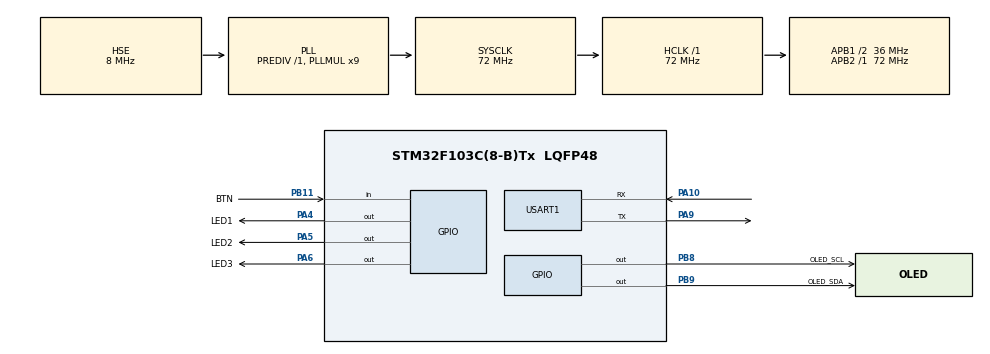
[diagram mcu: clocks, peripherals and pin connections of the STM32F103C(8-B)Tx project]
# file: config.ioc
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FREERTOS.Queues01=LEDCmdQueue,10,LEDCmdType,0,Dynamic,NULL,NULL;UARTStrQueue,5,16,1,Dynamic,NULL,NULL
FREERTOS.Tasks01=LEDTask,24,128,StartLEDTask,As weak,NULL,Dynamic,NULL,NULL;BtnTask,40,128,StartBtnTask,As weak,NULL,Dynamic,NULL,NULL;CommandTask,41,128,StartCommandTask,As weak,NULL,Dynamic,NULL,NULL
FREERTOS.configGENERATE_RUN_TIME_STATS=1
FREERTOS.configRECORD_STACK_HIGH_ADDRESS=1
FREERTOS.configUSE_STATS_FORMATTING_FUNCTIONS=0
Mcu.Family=STM32F1
Mcu.Name=STM32F103C(8-B)Tx
Mcu.Package=LQFP48
NVIC.PriorityGroup=NVIC_PRIORITYGROUP_4
NVIC.TIM4_IRQn=true\:15\:0\:false\:false\:true\:false\:false\:true\:true
NVIC.TimeBase=TIM4_IRQn
NVIC.TimeBaseIP=TIM4
NVIC.USART1_IRQn=true\:5\:0\:false\:false\:true\:true\:true\:true\:true
PA10.Mode=Asynchronous
PA10.Signal=USART1_RX
PA13.Mode=Serial_Wire
PA13.Signal=SYS_JTMS-SWDIO
PA14.Mode=Serial_Wire
PA14.Signal=SYS_JTCK-SWCLK
PA4.GPIO_Label=LED1
PA4.GPIO_Speed=GPIO_SPEED_FREQ_HIGH
PA4.Signal=GPIO_Output
PA5.GPIO_Label=LED2
PA5.GPIO_Speed=GPIO_SPEED_FREQ_HIGH
PA5.Signal=GPIO_Output
PA6.GPIO_Label=LED3
PA6.GPIO_Speed=GPIO_SPEED_FREQ_HIGH
PA6.Signal=GPIO_Output
PA9.Mode=Asynchronous
PA9.Signal=USART1_TX
PB11.GPIO_Label=BTN
PB11.GPIO_PuPd=GPIO_PULLUP
PB11.Signal=GPIO_Input
PB8.GPIO_Label=OLED_SCL
PB8.GPIO_ModeDefaultOutputPP=GPIO_MODE_OUTPUT_OD
PB8.GPIO_PuPd=GPIO_NOPULL
PB8.GPIO_Speed=GPIO_SPEED_FREQ_HIGH
PB8.PinState=GPIO_PIN_SET
PB8.Signal=GPIO_Output
PB9.GPIO_Label=OLED_SDA
PB9.GPIO_ModeDefaultOutputPP=GPIO_MODE_OUTPUT_OD
PB9.GPIO_PuPd=GPIO_NOPULL
PB9.GPIO_Speed=GPIO_SPEED_FREQ_HIGH
PB9.PinState=GPIO_PIN_SET
PB9.Signal=GPIO_Output
PD0-OSC_IN.Mode=HSE-External-Oscillator
PD0-OSC_IN.Signal=RCC_OSC_IN
PD1-OSC_OUT.Mode=HSE-External-Oscillator
PD1-OSC_OUT.Signal=RCC_OSC_OUT
ProjectManager.HeapSize=0x200
ProjectManager.StackSize=0x400
ProjectManager.TargetToolchain=CMake
RCC.AHBFreq_Value=72000000
RCC.APB1CLKDivider=RCC_HCLK_DIV2
RCC.APB1Freq_Value=36000000
RCC.APB1TimFreq_Value=72000000
RCC.APB2Freq_Value=72000000
RCC.APB2TimFreq_Value=72000000
RCC.HCLKFreq_Value=72000000
RCC.PLLMUL=RCC_PLL_MUL9
RCC.PLLSourceVirtual=RCC_PLLSOURCE_HSE
RCC.SYSCLKFreq_VALUE=72000000
RCC.SYSCLKSource=RCC_SYSCLKSOURCE_PLLCLK
RCC.USBFreq_Value=72000000
USART1.VirtualMode=VM_ASYNC
VP_FREERTOS_VS_CMSIS_V2.Mode=CMSIS_V2
VP_SYS_VS_tim4.Mode=TIM4
board=custom

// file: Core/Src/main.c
/* USER CODE BEGIN Header */
/**
  ******************************************************************************
  * @file           : main.c
  * @brief          : Main program body
  ******************************************************************************
  * @attention
  *
  * Copyright (c) 2026 STMicroelectronics.
  * All rights reserved.
  *
  * This software is licensed under terms that can be found in the LICENSE file
  * in the root directory of this software component.
  * If no LICENSE file comes with this software, it is provided AS-IS.
  *
  ******************************************************************************
  */
/* USER CODE END Header */
#include "main.h"
#include "cmsis_os.h"
#include "usart.h"
#include "gpio.h"

/* USER CODE BEGIN Includes */
#include "OLED.h"
#include "LEDType.h"
/* USER CODE END Includes */

void SystemClock_Config(void);
void MX_FREERTOS_Init(void);

int main(void)
{

  /* MCU Configuration--------------------------------------------------------*/

  /* Reset of all peripherals, Initializes the Flash interface and the Systick. */
  HAL_Init();

  /* Configure the system clock */
  SystemClock_Config();

  /* Initialize all configured peripherals */
  MX_GPIO_Init();
  MX_USART1_UART_Init();
  /* USER CODE BEGIN 2 */
  OLED_Init();
  OLED_ShowString(2, 1, "LEDCmd.num  :");
  OLED_ShowString(3, 1, "LEDCmd.state:");
  /* USER CODE END 2 */

  /* Init scheduler */
  osKernelInitialize();  /* Call init function for freertos objects (in cmsis_os2.c) */
  MX_FREERTOS_Init();

  /* Start scheduler */
  osKernelStart();

  /* We should never get here as control is now taken by the scheduler */

  /* Infinite loop */
  while (1)
  {

  }
}

void SystemClock_Config(void)
{
  RCC_OscInitTypeDef RCC_OscInitStruct = {0};
  RCC_ClkInitTypeDef RCC_ClkInitStruct = {0};

  /** Initializes the RCC Oscillators according to the specified parameters
  * in the RCC_OscInitTypeDef structure.
  */
  RCC_OscInitStruct.OscillatorType = RCC_OSCILLATORTYPE_HSE;
  RCC_OscInitStruct.HSEState = RCC_HSE_ON;
  RCC_OscInitStruct.HSEPredivValue = RCC_HSE_PREDIV_DIV1;
  RCC_OscInitStruct.HSIState = RCC_HSI_ON;
  RCC_OscInitStruct.PLL.PLLState = RCC_PLL_ON;
  RCC_OscInitStruct.PLL.PLLSource = RCC_PLLSOURCE_HSE;
  RCC_OscInitStruct.PLL.PLLMUL = RCC_PLL_MUL9;
  if (HAL_RCC_OscConfig(&RCC_OscInitStruct) != HAL_OK)
  {
    Error_Handler();
  }

  /** Initializes the CPU, AHB and APB buses clocks
  */
  RCC_ClkInitStruct.ClockType = RCC_CLOCKTYPE_HCLK|RCC_CLOCKTYPE_SYSCLK
                              |RCC_CLOCKTYPE_PCLK1|RCC_CLOCKTYPE_PCLK2;
  RCC_ClkInitStruct.SYSCLKSource = RCC_SYSCLKSOURCE_PLLCLK;
  RCC_ClkInitStruct.AHBCLKDivider = RCC_SYSCLK_DIV1;
  RCC_ClkInitStruct.APB1CLKDivider = RCC_HCLK_DIV2;
  RCC_ClkInitStruct.APB2CLKDivider = RCC_HCLK_DIV1;

  if (HAL_RCC_ClockConfig(&RCC_ClkInitStruct, FLASH_LATENCY_2) != HAL_OK)
  {
    Error_Handler();
  }
}

void HAL_TIM_PeriodElapsedCallback(TIM_HandleTypeDef *htim)
{
  if (htim->Instance == TIM4)
  {
    HAL_IncTick();
  }
}

void Error_Handler(void)
{
  __disable_irq();
  while (1)
  {
  }
}

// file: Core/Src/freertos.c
/* USER CODE BEGIN Header */
/**
 ******************************************************************************
 * File Name          : freertos.c
 * Description        : Code for freertos applications
 ******************************************************************************
 * @attention
 *
 * Copyright (c) 2026 STMicroelectronics.
 * All rights reserved.
 *
 * This software is licensed under terms that can be found in the LICENSE file
 * in the root directory of this software component.
 * If no LICENSE file comes with this software, it is provided AS-IS.
 *
 ******************************************************************************
 */
/* USER CODE END Header */
#include "main.h"
#include "FreeRTOS.h"
#include "task.h"

#include "cmsis_os.h"

/* USER CODE BEGIN Includes */
#include "OLED.h"
#include "usart.h"
#include "LEDType.h"
#include <stdint.h>
#include <stdio.h>
#include <string.h>

/* USER CODE END Includes */

/* Definitions for LEDTask */
osThreadId_t LEDTaskHandle;
const osThreadAttr_t LEDTask_attributes = {
  .name = "LEDTask",
  .stack_size = 128 * 4,
  .priority = (osPriority_t) osPriorityNormal,
};
/* Definitions for BtnTask */
osThreadId_t BtnTaskHandle;
const osThreadAttr_t BtnTask_attributes = {
  .name = "BtnTask",
  .stack_size = 128 * 4,
  .priority = (osPriority_t) osPriorityHigh,
};
/* Definitions for CommandTask */
osThreadId_t CommandTaskHandle;
const osThreadAttr_t CommandTask_attributes = {
  .name = "CommandTask",
  .stack_size = 128 * 4,
  .priority = (osPriority_t) osPriorityHigh1,
};
/* Definitions for LEDCmdQueue */
osMessageQueueId_t LEDCmdQueueHandle;
const osMessageQueueAttr_t LEDCmdQueue_attributes = {
  .name = "LEDCmdQueue"
};
/* Definitions for UARTStrQueue */
osMessageQueueId_t UARTStrQueueHandle;
const osMessageQueueAttr_t UARTStrQueue_attributes = {
  .name = "UARTStrQueue"
};

void StartLEDTask(void *argument);
void StartBtnTask(void *argument);
void StartCommandTask(void *argument);

void MX_FREERTOS_Init(void); /* (MISRA C 2004 rule 8.1) */

/* Hook prototypes */
void configureTimerForRunTimeStats(void);
unsigned long getRunTimeCounterValue(void);

/* USER CODE BEGIN 1 */
/* Functions needed when configGENERATE_RUN_TIME_STATS is on */
__weak void configureTimerForRunTimeStats(void) {}

__weak unsigned long getRunTimeCounterValue(void) { return 0; }
/* USER CODE END 1 */

void MX_FREERTOS_Init(void) {

  /* Create the queue(s) */
  /* creation of LEDCmdQueue */
  LEDCmdQueueHandle = osMessageQueueNew (10, sizeof(LEDCmdType), &LEDCmdQueue_attributes);

  /* creation of UARTStrQueue */
  UARTStrQueueHandle = osMessageQueueNew (5, 16, &UARTStrQueue_attributes);

  /* Create the thread(s) */
  /* creation of LEDTask */
  LEDTaskHandle = osThreadNew(StartLEDTask, NULL, &LEDTask_attributes);

  /* creation of BtnTask */
  BtnTaskHandle = osThreadNew(StartBtnTask, NULL, &BtnTask_attributes);

  /* creation of CommandTask */
  CommandTaskHandle = osThreadNew(StartCommandTask, NULL, &CommandTask_attributes);

}

__weak void StartLEDTask(void *argument)
{
  for(;;)
  {
    osDelay(1);
  }
}

__weak void StartBtnTask(void *argument)
{
  for(;;)
  {
    osDelay(1);
  }
}

__weak void StartCommandTask(void *argument)
{
  for(;;)
  {
    osDelay(1);
  }
}
